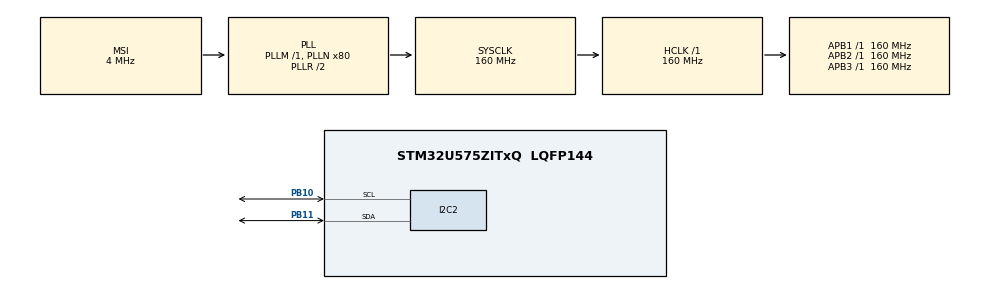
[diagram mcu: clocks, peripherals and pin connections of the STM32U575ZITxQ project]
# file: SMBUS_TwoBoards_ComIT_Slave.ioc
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CORTEX_M33_NS.userName=CORTEX_M33
I2C2.SMBusDualAddressMode=SMBUS_DUALADDRESS_ENABLE
I2C2.SMBusOwnAddress=0x42
I2C2.SMBusOwnAddress2=0xFF
I2C2.SMBusPacketErrorCheckMode=SMBUS_PEC_ENABLE
I2C2.Timeout=0x000087A1
I2C2.Timing=0x30909DEC
Mcu.Family=STM32U5
Mcu.Name=STM32U575ZITxQ
Mcu.Package=LQFP144
NVIC.I2C2_ER_IRQn=true\:0\:0\:false\:false\:true\:true\:true\:true
NVIC.I2C2_EV_IRQn=true\:0\:0\:false\:false\:true\:true\:true\:true
NVIC.PriorityGroup=NVIC_PRIORITYGROUP_4
PB10.GPIO_Pu=GPIO_PULLUP
PB10.GPIO_Speed=GPIO_SPEED_FREQ_VERY_HIGH
PB10.Mode=SMBus-two-wire-Interface
PB10.Signal=I2C2_SCL
PB11.GPIO_Pu=GPIO_PULLUP
PB11.GPIO_Speed=GPIO_SPEED_FREQ_VERY_HIGH
PB11.Mode=SMBus-two-wire-Interface
PB11.Signal=I2C2_SDA
PWR.PowerMode=PWR_SMPS_SUPPLY
ProjectManager.HeapSize=0x200
ProjectManager.StackSize=0x400
ProjectManager.TargetToolchain=EWARM V8.50
RCC.ADCFreq_Value=16000000
RCC.AHBFreq_Value=160000000
RCC.APB1Freq_Value=160000000
RCC.APB1TimFreq_Value=160000000
RCC.APB2Freq_Value=160000000
RCC.APB2TimFreq_Value=160000000
RCC.APB3Freq_Value=160000000
RCC.CortexFreq_Value=160000000
RCC.DACCLockSelectionVirtual=RCC_DAC1CLKSOURCE_LSI
RCC.DACCLockSelectionVirtualString=RCC_DAC1CLKSOURCE_LSI
RCC.EPOD_VALUE=4000000
RCC.HCLKFreq_Value=160000000
RCC.HSE_VALUE=16000000
RCC.HSI48_VALUE=48000000
RCC.HSI_VALUE=16000000
RCC.LSE_VALUE=32768
RCC.LSIDIV_VALUE=32000
RCC.MSI_VALUE=4000000
RCC.PLLN=80
RCC.SYSCLKFreq_VALUE=160000000
RCC.SYSCLKSource=RCC_SYSCLKSOURCE_PLLCLK
RCC.USBFreq_Value=48000000
RCC.VCOOutputFreq_Value=320000000
VP_ICACHE_VS_ICACHE.Mode=DirectMappedCache
VP_LPBAMQUEUE_VS_QUEUE.Mode=QUEUEMODE
VP_LPBAM_VS_SIG1.Mode=SmartRun
VP_LPBAM_VS_SIG4.Mode=LPDMA1
VP_PWR_VS_DBSignals.Mode=DisableDeadBatterySignals
VP_PWR_VS_LPOM.Mode=PowerOptimisation
VP_PWR_VS_SECSignals.Mode=Security/Privilege
board=custom

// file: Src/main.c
/* USER CODE BEGIN Header */
/**
  ******************************************************************************
  * @file           : main.c
  * @brief          : Main program body
  ******************************************************************************
  * @attention
  *
  * Copyright (c) 2021 STMicroelectronics.
  * All rights reserved.
  *
  * This software is licensed under terms that can be found in the LICENSE file
  * in the root directory of this software component.
  * If no LICENSE file comes with this software, it is provided AS-IS.
  *
  ******************************************************************************
  */
/* USER CODE END Header */
#include "main.h"

/* USER CODE BEGIN PD */
#define SMBUS_ADDRESS          0x42
#define SMBUS_PEC_SIZE         0x1

/* Address match */
__IO uint32_t SlaveAddrMatchCode = 0;

/* Buffer used for transmission */
uint8_t aTxBuffer[] = " ****SMBUS_TwoBoards communication using Interrupts****  ****SMBUS_TwoBoards communication using Interrupts****  ****SMBUS_TwoBoards communication using Interrupts**** ";

/* Buffer used for data and PEC reception */
uint8_t aRxBuffer[RXBUFFERSIZE + SMBUS_PEC_SIZE];
/* USER CODE END PD */

SMBUS_HandleTypeDef hsmbus2;

void SystemClock_Config(void);
static void SystemPower_Config(void);
static void MX_GPIO_Init(void);
static void MX_ICACHE_Init(void);
static void MX_I2C2_SMBUS_Init(void);
/* USER CODE BEGIN PFP */
static uint16_t Buffercmp(uint8_t* pBuffer1, uint8_t* pBuffer2, uint16_t BufferLength);
/* USER CODE END PFP */

int main(void)
{

  /* MCU Configuration--------------------------------------------------------*/

  /* Reset of all peripherals, Initializes the Flash interface and the Systick. */
  HAL_Init();

  /* Configure the System Power */
  SystemPower_Config();

  /* Configure the system clock */
  SystemClock_Config();

  /* USER CODE BEGIN SysInit */
  /* Configure LED1 and LED3 */
  BSP_LED_Init(LED1);
  BSP_LED_Init(LED2);
  BSP_LED_Init(LED3);
  /* USER CODE END SysInit */

  /* Initialize all configured peripherals */
  MX_GPIO_Init();
  MX_ICACHE_Init();
  MX_I2C2_SMBUS_Init();
  /* USER CODE BEGIN 2 */
  /* Enable the Analog SMBUS Filter */
  HAL_SMBUS_ConfigAnalogFilter(&hsmbus2,SMBUS_ANALOGFILTER_ENABLE);

  /* Enable address Match detect with interrupt */
  HAL_SMBUS_EnableListen_IT(&hsmbus2);
  /* Wait until address matched */
  while(SlaveAddrMatchCode != SMBUS_ADDRESS);
  SlaveAddrMatchCode = 0;
  BSP_LED_Off(LED2);

  /* The board receives the message and sends it back */

  /*##-2- Put SMBUS peripheral in reception process ############################*/
  if(HAL_SMBUS_Slave_Receive_IT(&hsmbus2, (uint8_t *)aRxBuffer, RXBUFFERSIZE + SMBUS_PEC_SIZE, SMBUS_FIRST_AND_LAST_FRAME_WITH_PEC) != HAL_OK)
  {
    /* Transfer error in reception process */
    Error_Handler();
  }
  while (hsmbus2.State != HAL_SMBUS_STATE_READY);

  /* Compare PEC register and sent PEC #######################################*/
  if(aRxBuffer[RXBUFFERSIZE + SMBUS_PEC_SIZE - 1] != hsmbus2.Instance->PECR)
  {
    /* Processing Error */
    Error_Handler();
  }

  /* Turn LED1 on: Transfer in reception process is correct */
  BSP_LED_On(LED1);

  /*##-3- Start the transmission process #####################################*/
  /* While the SMBUS in reception process, user can transmit data through
     "aTxBuffer" buffer */

  /* Enable address Match detect with interrupt */
  HAL_SMBUS_EnableListen_IT(&hsmbus2);
  /* Wait until address matched */
  while(SlaveAddrMatchCode != SMBUS_ADDRESS);
  SlaveAddrMatchCode = 0;

  /*##-2- Put SMBUS peripheral in transmission process ############################*/
  if(HAL_SMBUS_Slave_Transmit_IT(&hsmbus2, (uint8_t*)aTxBuffer, TXBUFFERSIZE + SMBUS_PEC_SIZE, SMBUS_FIRST_AND_LAST_FRAME_WITH_PEC)!= HAL_OK)
  {
    /* Transfer error in transmission process */
    Error_Handler();
  }
  while (hsmbus2.State != HAL_SMBUS_STATE_READY);
  /* Turn LED1 off: Transfer in transmission process is correct */
  BSP_LED_Off(LED1);

    /*##-4- Compare the sent and received buffers ##############################*/
  if(Buffercmp((uint8_t*)aTxBuffer,(uint8_t*)aRxBuffer,RXBUFFERSIZE))
  {
    /* Processing Error */
    Error_Handler();
  }

  /* USER CODE END 2 */

  /* Infinite loop */
  while (1)
  {

  }
}

void SystemClock_Config(void)
{
  RCC_OscInitTypeDef RCC_OscInitStruct = {0};
  RCC_ClkInitTypeDef RCC_ClkInitStruct = {0};

  /** Configure the main internal regulator output voltage
  */
  if (HAL_PWREx_ControlVoltageScaling(PWR_REGULATOR_VOLTAGE_SCALE1) != HAL_OK)
  {
    Error_Handler();
  }

  /** Initializes the CPU, AHB and APB buses clocks
  */
  RCC_OscInitStruct.OscillatorType = RCC_OSCILLATORTYPE_MSI;
  RCC_OscInitStruct.MSIState = RCC_MSI_ON;
  RCC_OscInitStruct.MSICalibrationValue = RCC_MSICALIBRATION_DEFAULT;
  RCC_OscInitStruct.MSIClockRange = RCC_MSIRANGE_4;
  RCC_OscInitStruct.PLL.PLLState = RCC_PLL_ON;
  RCC_OscInitStruct.PLL.PLLSource = RCC_PLLSOURCE_MSI;
  RCC_OscInitStruct.PLL.PLLMBOOST = RCC_PLLMBOOST_DIV1;
  RCC_OscInitStruct.PLL.PLLM = 1;
  RCC_OscInitStruct.PLL.PLLN = 80;
  RCC_OscInitStruct.PLL.PLLP = 2;
  RCC_OscInitStruct.PLL.PLLQ = 2;
  RCC_OscInitStruct.PLL.PLLR = 2;
  RCC_OscInitStruct.PLL.PLLRGE = RCC_PLLVCIRANGE_0;
  RCC_OscInitStruct.PLL.PLLFRACN = 0;
  if (HAL_RCC_OscConfig(&RCC_OscInitStruct) != HAL_OK)
  {
    Error_Handler();
  }

  /** Initializes the CPU, AHB and APB buses clocks
  */
  RCC_ClkInitStruct.ClockType = RCC_CLOCKTYPE_HCLK|RCC_CLOCKTYPE_SYSCLK
                              |RCC_CLOCKTYPE_PCLK1|RCC_CLOCKTYPE_PCLK2
                              |RCC_CLOCKTYPE_PCLK3;
  RCC_ClkInitStruct.SYSCLKSource = RCC_SYSCLKSOURCE_PLLCLK;
  RCC_ClkInitStruct.AHBCLKDivider = RCC_SYSCLK_DIV1;
  RCC_ClkInitStruct.APB1CLKDivider = RCC_HCLK_DIV1;
  RCC_ClkInitStruct.APB2CLKDivider = RCC_HCLK_DIV1;
  RCC_ClkInitStruct.APB3CLKDivider = RCC_HCLK_DIV1;

  if (HAL_RCC_ClockConfig(&RCC_ClkInitStruct, FLASH_LATENCY_4) != HAL_OK)
  {
    Error_Handler();
  }
}

/**
  * @brief Power Configuration
  * @retval None
  */
static void SystemPower_Config(void)
{

  /*
   * Disable the internal Pull-Up in Dead Battery pins of UCPD peripheral
   */
  HAL_PWREx_DisableUCPDDeadBattery();

  /*
   * Switch to SMPS regulator instead of LDO
   */
  if (HAL_PWREx_ConfigSupply(PWR_SMPS_SUPPLY) != HAL_OK)
  {
    Error_Handler();
  }
}

static void MX_I2C2_SMBUS_Init(void)
{

  hsmbus2.Instance = I2C2;
  hsmbus2.Init.Timing = 0x30909DEC;
  hsmbus2.Init.AnalogFilter = SMBUS_ANALOGFILTER_ENABLE;
  hsmbus2.Init.OwnAddress1 = 0x42;
  hsmbus2.Init.AddressingMode = SMBUS_ADDRESSINGMODE_7BIT;
  hsmbus2.Init.DualAddressMode = SMBUS_DUALADDRESS_ENABLE;
  hsmbus2.Init.OwnAddress2 = 0xFF;
  hsmbus2.Init.OwnAddress2Masks = SMBUS_OA2_NOMASK;
  hsmbus2.Init.GeneralCallMode = SMBUS_GENERALCALL_DISABLE;
  hsmbus2.Init.NoStretchMode = SMBUS_NOSTRETCH_DISABLE;
  hsmbus2.Init.PacketErrorCheckMode = SMBUS_PEC_ENABLE;
  hsmbus2.Init.PeripheralMode = SMBUS_PERIPHERAL_MODE_SMBUS_SLAVE;
  hsmbus2.Init.SMBusTimeout = 0x000087A1;
  if (HAL_SMBUS_Init(&hsmbus2) != HAL_OK)
  {
    Error_Handler();
  }

  /** Configure Digital filter
  */
  if (HAL_SMBUS_ConfigDigitalFilter(&hsmbus2, 0) != HAL_OK)
  {
    Error_Handler();
  }

}

static void MX_ICACHE_Init(void)
{

  /** Enable instruction cache in 1-way (direct mapped cache)
  */
  if (HAL_ICACHE_ConfigAssociativityMode(ICACHE_1WAY) != HAL_OK)
  {
    Error_Handler();
  }
  if (HAL_ICACHE_Enable() != HAL_OK)
  {
    Error_Handler();
  }

}

static void MX_GPIO_Init(void)
{

  /* GPIO Ports Clock Enable */
  __HAL_RCC_GPIOB_CLK_ENABLE();

}

/* USER CODE BEGIN 4 */
/**
  * @brief  SMBUS error callbacks.
  * @param  SMBUSHandle: SMBUS handle
  * @note   This example shows a simple way to report transfer error, and you can
  *         add your own implementation.
  * @retval None
  */
void HAL_SMBUS_ErrorCallback(SMBUS_HandleTypeDef *SMBUSHandle)
{
  /** Error_Handler() function is called when error occurs.
    * 1- When Slave doesn't acknowledge its address, Master restarts communication.
    * 2- When Master doesn't acknowledge the last data transferred, Slave doesn't care in this example.
    */
  if (HAL_SMBUS_GetError(SMBUSHandle) != HAL_SMBUS_ERROR_ACKF)
  {
    /* Turn Off LED1 */
    BSP_LED_Off(LED1);

    /* Turn On LED3 */
    BSP_LED_On(LED3);
  }
}

/**
  * @brief  Slave Address Match callbacks.
  * @param  hsmbus : Pointer to a SMBUS_HandleTypeDef structure that contains
  *                the configuration information for the specified SMBUS.
  * @retval None
  */
void HAL_SMBUS_AddrCallback(SMBUS_HandleTypeDef *hsmbus,uint8_t TransferDirection, uint16_t AddrMatchCode)
{
    SlaveAddrMatchCode = (AddrMatchCode << 1);
    UNUSED(TransferDirection);
}

/**
  * @brief  Compares two buffers.
  * @param  pBuffer1, pBuffer2: buffers to be compared.
  * @param  BufferLength: buffer's length
  * @retval 0  : pBuffer1 identical to pBuffer2
  *         >0 : pBuffer1 differs from pBuffer2
  */
static uint16_t Buffercmp(uint8_t* pBuffer1, uint8_t* pBuffer2, uint16_t BufferLength)
{
  while (BufferLength--)
  {
    if ((*pBuffer1) != *pBuffer2)
    {
      return BufferLength;
    }
    pBuffer1++;
    pBuffer2++;
  }

  return 0;
}
/* USER CODE END 4 */

void Error_Handler(void)
{
  /* USER CODE BEGIN Error_Handler_Debug */
  /* Turn LED1 off */
  BSP_LED_Off(LED1);
  /* Turn LED3 on */
  BSP_LED_On(LED3);
  while(1)
  {
  }
  __disable_irq();
  while (1)
  {
  }
  /* USER CODE END Error_Handler_Debug */
}
